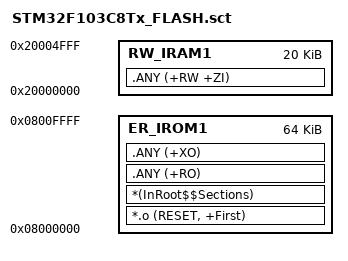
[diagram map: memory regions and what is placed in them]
; ============================================================
; STM32F103C8Tx 链接器分散加载文件 (Scatter File)
; Flash: 64KB → 0x08000000 ~ 0x0800FFFF
; SRAM:  20KB → 0x20000000 ~ 0x20004FFF
; ============================================================

LR_IROM1 0x08000000 0x00010000  {    ; 加载区: Flash 64KB
  ER_IROM1 0x08000000 0x00010000  {  ; 执行区: 全部 Flash
   *.o (RESET, +First)
   *(InRoot$$Sections)
   .ANY (+RO)
   .ANY (+XO)
  }
  RW_IRAM1 0x20000000 0x00005000  {  ; 数据区: SRAM 20KB
   .ANY (+RW +ZI)
  }
}
